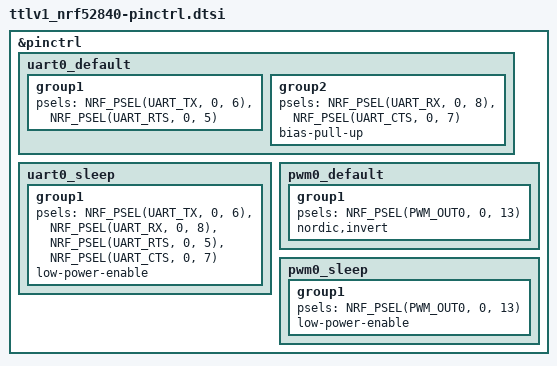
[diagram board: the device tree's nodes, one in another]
/*
 * Copyright (c) 2022 Nordic Semiconductor
 * SPDX-License-Identifier: Apache-2.0
 */

&pinctrl {
	uart0_default: uart0_default {
		group1 {
			psels = <NRF_PSEL(UART_TX, 0, 6)>,
				<NRF_PSEL(UART_RTS, 0, 5)>;
		};
		group2 {
			psels = <NRF_PSEL(UART_RX, 0, 8)>,
				<NRF_PSEL(UART_CTS, 0, 7)>;
			bias-pull-up;
		};
	};

	uart0_sleep: uart0_sleep {
		group1 {
			psels = <NRF_PSEL(UART_TX, 0, 6)>,
				<NRF_PSEL(UART_RX, 0, 8)>,
				<NRF_PSEL(UART_RTS, 0, 5)>,
				<NRF_PSEL(UART_CTS, 0, 7)>;
			low-power-enable;
		};
	};

	pwm0_default: pwm0_default {
		group1 {
			psels = <NRF_PSEL(PWM_OUT0, 0, 13)>;
			nordic,invert;
		};
	};

	pwm0_sleep: pwm0_sleep {
		group1 {
			psels = <NRF_PSEL(PWM_OUT0, 0, 13)>;
			low-power-enable;
		};
	};
};
